# Z20K14xM register map
Vendor: Zhixin Semiconductor; Series: Z20K14xM; File version: 0.1.0
CPU: CM4 r0p1, little endian, no MPU, FPU, 4 interrupt priority bits
Registers are 32-bit, read-write, reset 0x0 unless marked. A register's access mark holds for its fields unless they carry their own. Offsets are from the block's base; [hi:lo] are bit positions; {n}, {i} and the like mark numbered series; 'fields as' and 'values as' point back to an identical list.

## CAN0
Base 0x40024000
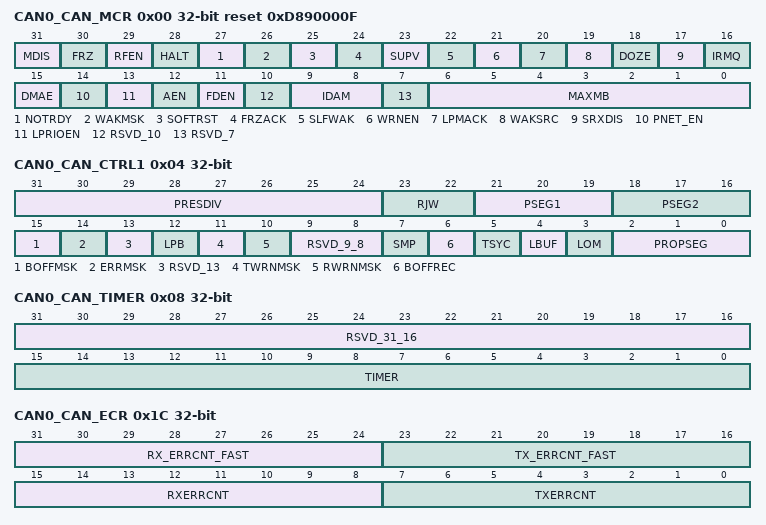
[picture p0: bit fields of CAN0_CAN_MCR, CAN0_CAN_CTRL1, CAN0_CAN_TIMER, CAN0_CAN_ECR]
0x00 CAN0_CAN_MCR reset 0xD890000F — CAN module configure register(CAN_MCR)
  [31] MDIS — Module Disable
  [30] FRZ — Freeze Enable
  [29] RFEN — Legacy Rx FIFO Enable
  [28] HALT — Halt CAN
  [27] NOTRDY — CAN Not Ready
  [26] WAKMSK — Wake Up Interrupt Mask
  [25] SOFTRST — Soft Reset
  [24] FRZACK — Freeze Mode Acknowledge
  [23] SUPV — Supervisor Mode
  [22] SLFWAK — Self Wake Up
  [21] WRNEN — Warning Interrupt Enable
  [20] LPMACK — Low-Power Mode Acknowledge
  [19] WAKSRC — Wake Up Source
  [18] DOZE — Doze Mode Enable
  [17] SRXDIS — Self Reception Disable
  [16] IRMQ — Individual Rx Masking And Queue Enable
  [15] DMAE — DMA Enable
  [14] PNET_EN — Pretended Networking Enable
  [13] LPRIOEN — Local Priority Enable
  [12] AEN — Abort Enable
  [11] FDEN — CAN FD operation enable
  [10] RSVD_10 — reserve
  [9:8] IDAM — ID Acceptance Mode
  [7] RSVD_7 — reserve
  [6:0] MAXMB — Reserved
0x04 CAN0_CAN_CTRL1 — CONTROL 1 register(CAN_CTRL1)
  [31:24] PRESDIV — Prescaler Division Factor
  [23:22] RJW — Resync Jump Width
  [21:19] PSEG1 — Phase segment 1
  [18:16] PSEG2 — Phase segment 2
  [15] BOFFMSK — Bus off interrupt mask
  [14] ERRMSK — Error interrupt mask
  [13] RSVD_13 — reserve
  [12] LPB — Loop Back Mode
  [11] TWRNMSK — Tx Warning Interrupt Mask
  [10] RWRNMSK — Rx Warning Interrupt Mask
  [9:8] RSVD_9_8 — reserve
  [7] SMP — CAN Bit Sampling
  [6] BOFFREC — Bus Off Recovery
  [5] TSYC — Timer Sync
  [4] LBUF — Lowest Buffer Transmitted First
  [3] LOM — Listen-Only Mode
  [2:0] PROPSEG — Propagation Segment
0x08 CAN0_CAN_TIMER — Free Running Timer register(CAN_TIMER)
  [31:16] RSVD_31_16 — reserve
  [15:0] TIMER — free running counter value
0x10 CAN0_CAN_RXMGMSK reset not defined — Rx mailbox global mask register(CAN_RXMGMSK)
  [31:0] MG — Rx mailbox global mask
0x14 CAN0_CAN_RX14MASK reset not defined — Rx 14 mask register(CAN_RX14MASK)
  [31:0] RX14M — Rx Buffer 14 Mask Bits
0x18 CAN0_CAN_RX15MASK reset not defined — Rx 15 mask register(CAN_RX15MASK)
  [31:0] RX15M — Rx Buffer 15 Mask Bits
0x1C CAN0_CAN_ECR — Error counter register(CAN_ECR)
  [31:24] RX_ERRCNT_FAST — Receive Error Counter for fast bits
  [23:16] TX_ERRCNT_FAST — Transmit Error Counter for fast bits
  [15:8] RXERRCNT — Receive Error Counter
  [7:0] TXERRCNT — Transmit Error Counter
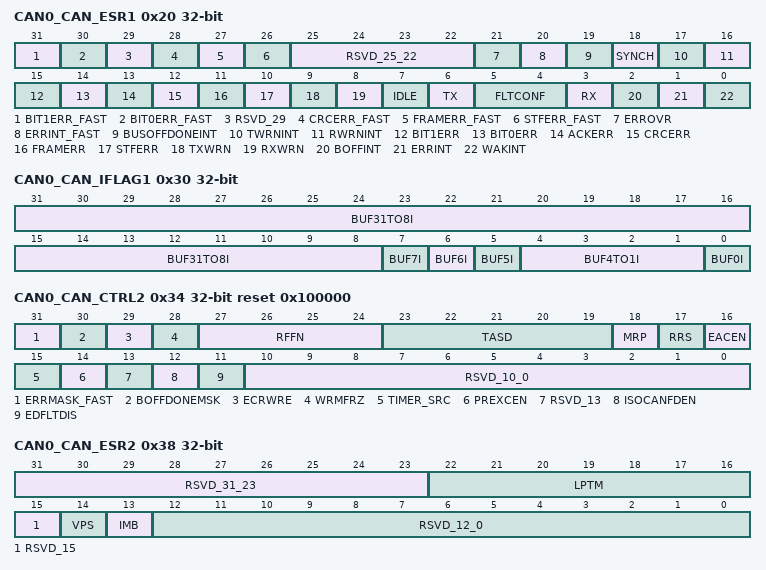
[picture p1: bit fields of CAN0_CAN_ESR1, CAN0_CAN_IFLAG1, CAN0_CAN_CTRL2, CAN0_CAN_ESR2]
0x20 CAN0_CAN_ESR1 — CAN error status register(CAN_ESR1)
  [31] BIT1ERR_FAST — Bit1 error in CAN_FD data phase
  [30] BIT0ERR_FAST — Bit0 error in CAN_FD data phase
  [29] RSVD_29 — reserve
  [28] CRCERR_FAST — CRC error in CAN_FD CRC phase
  [27] FRAMERR_FAST — Frame error of CAN_FD data phase
  [26] STFERR_FAST — Stuff erro of CAN_FD data phase.
  [25:22] RSVD_25_22 — reserve
  [21] ERROVR — error of overrun
  [20] ERRINT_FAST — error interrupt of errors detect in CAN_FD data phase
  [19] BUSOFFDONEINT — Bus off done interrupt
  [18] SYNCH — Synchronous
  [17] TWRNINT — Tx Warning Interrupt
  [16] RWRNINT — Rx warning Interrupt
  [15] BIT1ERR — Bit error of CAN non-fd
  [14] BIT0ERR — Bit0 error of CAN non-fd
  [13] ACKERR — Acknowledge error of non-fd
  [12] CRCERR — CRC error of non-fd
  [11] FRAMERR — frame error of non-fd
  [10] STFERR — stuff erro of non-fd
  [9] TXWRN — tx warning
  [8] RXWRN — Rx warning
  [7] IDLE
  [6] TX — Flexcan in transmission
  [5:4] FLTCONF — Fault confinement state
  [3] RX — Flexcan in Reception
  [2] BOFFINT — bus off interrupt
  [1] ERRINT — error interrupt
  [0] WAKINT — wakeup interrupt
0x24 CAN0_CAN_IMASK2 — Interrupt mask 2 register(CAN_IMASK2)
  [31:0] BUF63TO32M — Buffer MB i Mask
0x28 CAN0_CAN_IMASK1 — Interrupt mask 1 register(CAN_IMASK1)
  [31:0] BUF31TO0M — Buffer MB31 -0 Mask
0x2C CAN0_CAN_IFLAG2 — Interrupt flag 2 register(CAN_IFLAG2)
  [31:0] BUF63TO32I — Buffer MB63-32 Mask
0x30 CAN0_CAN_IFLAG1 — Interrupt flag 1 register(CAN_IFLAG1)
  [31:8] BUF31TO8I — Buffer8-31 interrupt
  [7] BUF7I — Buffer7 interrupt
  [6] BUF6I — Buffer6 interrupt
  [5] BUF5I — Buffer5 interrupt
  [4:1] BUF4TO1I — Buffer 1-4 interrupt
  [0] BUF0I — Buffer0 interrupt
0x34 CAN0_CAN_CTRL2 reset 0x100000 — Control 2 register(CAN_CTRL2)
  [31] ERRMASK_FAST — error mask of can-fd
  [30] BOFFDONEMSK — bus off done mask
  [29] ECRWRE — error correction register write enable
  [28] WRMFRZ — Write-Access To Memory In Freeze Mode
  [27:24] RFFN — Number of Rx FIFO Filters
  [23:19] TASD — Tx Arbitration Start Delay
  [18] MRP — Mailboxes Reception Priority
  [17] RRS — Remote Request Storing
  [16] EACEN — Entire Frame Arbitration Field Comparison Enable For Rx Mailboxes
  [15] TIMER_SRC — Timer Source
  [14] PREXCEN — Protocol Exception Enable
  [13] RSVD_13 — reserve
  [12] ISOCANFDEN — ISO CAN FD Enable
  [11] EDFLTDIS — Edge Filter Disable
  [10:0] RSVD_10_0 — reserve
0x38 CAN0_CAN_ESR2 — Error and Status 2 register(CAN_ESR2)
  [31:23] RSVD_31_23 — reserve
  [22:16] LPTM — Lowest Priority Tx Mailbox
  [15] RSVD_15 — reserve
  [14] VPS — Valid Priority Status
  [13] IMB — Inactive Mailbox
  [12:0] RSVD_12_0 — reserve
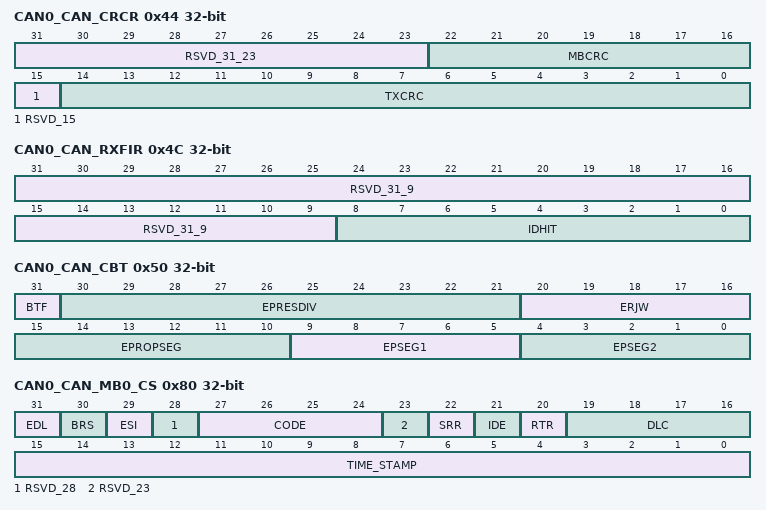
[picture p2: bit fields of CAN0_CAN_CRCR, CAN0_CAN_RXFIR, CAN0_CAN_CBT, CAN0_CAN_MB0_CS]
0x44 CAN0_CAN_CRCR — CRC register(CAN_CRCR)
  [31:23] RSVD_31_23 — reserve
  [22:16] MBCRC — CRC Mailbox
  [15] RSVD_15 — reserve
  [14:0] TXCRC — Transmitted CRC Value
0x48 CAN0_CAN_RXFGMASK reset not defined — Leagacy FIFO global mask register(CAN_RXFGMASK)
  [31:0] FGM — Rx FIFO Global Mask Bits
0x4C CAN0_CAN_RXFIR reset not defined — RX FIFO ID indicator(CAN_RXFIR)
  [31:9] RSVD_31_9 — reserve
  [8:0] IDHIT — ID Hit incicator
0x50 CAN0_CAN_CBT — CAN bit timing register(CAN_CBT)
  [31] BTF — Bit Timing Format Enable
  [30:21] EPRESDIV — Extended Prescaler Division Factor
  [20:16] ERJW — Extended Resync Jump Width
  [15:10] EPROPSEG — Extended Propagation Segment
  [9:5] EPSEG1 — Extended Phase Segment 1
  [4:0] EPSEG2 — Extended Phase Segment 2
0x68 CAN0_CAN_IMASK4 — Interrupt mask 4 register(CAN_IMASK4)
  [31:0] BUF127TO96M — Buffer MB 127-96 Mask
0x6C CAN0_CAN_IMASK3 — Interrupt mask 3 register(CAN_IMASK3)
  [31:0] BUF95TO64M — Buffer MB 95-64 Mask
0x70 CAN0_CAN_IFLAG4 — Interrupt flag 4 register(CAN_IFLAG4)
  [31:0] BUF127TO96I — Buffer MB 127-96 Interrupt
0x74 CAN0_CAN_IFLAG3 — Interrupt flag 3 register(CAN_IFLAG3)
  [31:0] BUF95TO64I — Buffer MB 95-64 Interrupt
0x80 CAN0_CAN_MB0_CS reset not defined — reserve
  [31] EDL — Extended Data Length
  [30] BRS — Bit Rate Switch
  [29] ESI — Error State Indicator
  [28] RSVD_28 — reserve
  [27:24] CODE — Message Buffer Code
  [23] RSVD_23 — reserve
  [22] SRR — Substitute Remote Request
  [21] IDE — ID Extended Bit
  [20] RTR — Remote Transmission Request
  [19:16] DLC — Length of Data in Bytes
  [15:0] TIME_STAMP — Free-Running Counter Time Stamp
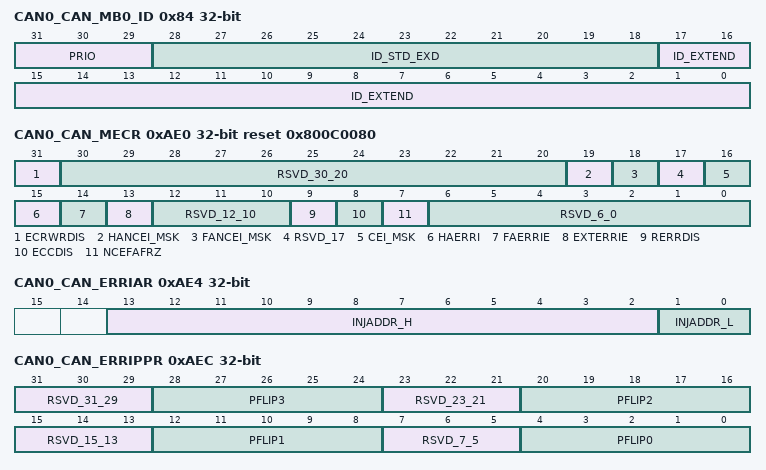
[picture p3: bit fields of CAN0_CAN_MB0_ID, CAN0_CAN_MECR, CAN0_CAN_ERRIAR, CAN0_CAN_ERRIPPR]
0x84 CAN0_CAN_MB0_ID reset not defined — Message buffer ID register(CAN_MB0_ID)
  [31:29] PRIO — Local priority
  [28:18] ID_STD_EXD — Frame Identifier
  [17:0] ID_EXTEND — Frame Identifier
0x88 CAN0_CAN_MB0_DATA03 reset not defined — Message buffer date03 register(CAN_MB0_DATA03)
  [31:0] DATA_BYTE03
0x8C CAN0_CAN_MB0_DATA47 reset not defined — Message buffer date47 register(CAN_MB0_DAT47)
  [31:0] DATA_BYTE47 — data byte0-3
0x880 CAN0_CAN_RXIMRn reset not defined — RX individual mask register(CAN_RXIMRn)
  [31:0] MI — Individual Mask Bits
0xAE0 CAN0_CAN_MECR reset 0x800C0080 — Memory error control register(CAN_MECR)
  [31] ECRWRDIS — Error Configuration Register Write Disable
  [30:20] RSVD_30_20 — reserve
  [19] HANCEI_MSK — Host Access with Non-Correctable Errors Interrupt Mask
  [18] FANCEI_MSK — CAN Access With Non-Correctable Errors Interrupt Mask
  [17] RSVD_17 — reserve
  [16] CEI_MSK — Correctable Errors Interrupt Mask
  [15] HAERRI — Host Access Error Injection Enable
  [14] FAERRIE — CAN Access Error Injection Enable
  [13] EXTERRIE — Extended Error Injection
  [12:10] RSVD_12_10 — reserve
  [9] RERRDIS — Error Report Disable
  [8] ECCDIS — Error Correction Disable
  [7] NCEFAFRZ — Non-Correctable Errors In CAN Access Put Device In Freeze Mode
  [6:0] RSVD_6_0 — reserve
0xAE4 CAN0_CAN_ERRIAR — Error injection address regsiter(CAN_ERRIAR)
  [13:2] INJADDR_H — Error Injection Address High
  [1:0] INJADDR_L — Error Injection Address Low
0xAE8 CAN0_CAN_ERRIDPR — Error injection data pattern register(CAN_ERRIDPR)
  [31:0] DFLIP — Data Flip Pattern
0xAEC CAN0_CAN_ERRIPPR — Error injection parity pattern register(CAN_ERRIPPR)
  [31:29] RSVD_31_29 — reserve
  [28:24] PFLIP3 — Parity Flip Pattern For Byte 3 (most significant)
  [23:21] RSVD_23_21 — reserve
  [20:16] PFLIP2 — Parity Flip Pattern For Byte 2
  [15:13] RSVD_15_13 — reserve
  [12:8] PFLIP1 — Parity Flip Pattern For Byte 1
  [7:5] RSVD_7_5 — reserve
  [4:0] PFLIP0 — Parity Flip Pattern For Byte 0
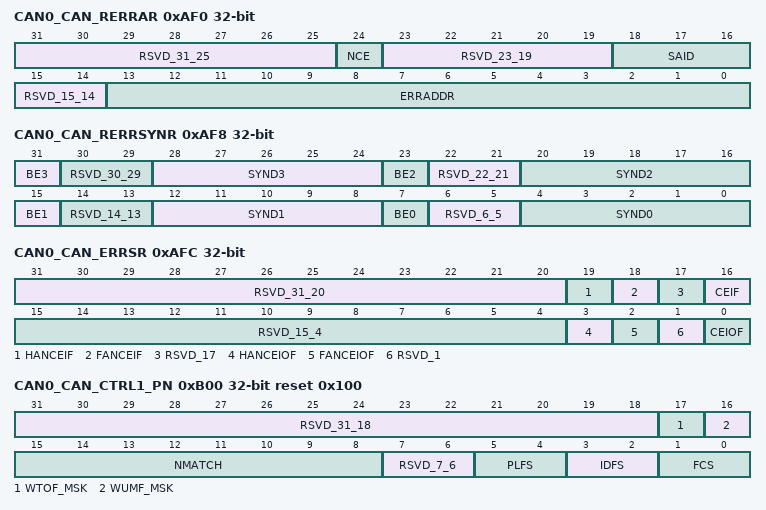
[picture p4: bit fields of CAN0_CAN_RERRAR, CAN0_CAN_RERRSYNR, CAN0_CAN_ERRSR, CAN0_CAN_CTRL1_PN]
0xAF0 CAN0_CAN_RERRAR — Error report address register(CAN_RERRAR)
  [31:25] RSVD_31_25 — reserve
  [24] NCE — Non-Correctable Error: Indicates that the report is due to a non-correctable error
  [23:19] RSVD_23_19 — reserve
  [18:16] SAID — SAID[2]: Identification of the requestor of the memory read request SAID[1]: Details of FlexCAN operation SAID[0]: Operation that requested the memory read
  [15:14] RSVD_15_14 — reserve
  [13:0] ERRADDR — Address Where the Error was Detected
0xAF4 CAN0_CAN_RERRDR — Error report data register(CAN_RERRDR)
  [31:0] RDATA — Raw data word read from memory with error
0xAF8 CAN0_CAN_RERRSYNR — Error report Syndrome reigster(CAN_RERRSYNR)
  [31] BE3 — Byte Enabled For Byte 3 (most significant)
  [30:29] RSVD_30_29 — reserve
  [28:24] SYND3 — Error Syndrome For Byte 3 (most significant)
  [23] BE2 — Error Syndrome For Byte 3 (most significant)
  [22:21] RSVD_22_21 — reserve
  [20:16] SYND2 — Error Syndrome For Byte 2
  [15] BE1 — Byte Enabled For Byte 1
  [14:13] RSVD_14_13 — reserve
  [12:8] SYND1 — Error Syndrome For Byte 1
  [7] BE0 — Byte Enabled For Byte 0 (least significant)
  [6:5] RSVD_6_5 — reserve
  [4:0] SYND0 — Error Syndrome For Byte 0
0xAFC CAN0_CAN_ERRSR — Error status register(CAN_ERRSR)
  [31:20] RSVD_31_20 — reserve
  [19] HANCEIF — Host Access with Non-Correctable Error Interrupt Flag
  [18] FANCEIF — CAN Access with Non-Correctable Error Interrupt Flag
  [17] RSVD_17 — reserve
  [16] CEIF — Correctable Error Interrupt Flag
  [15:4] RSVD_15_4 — reserve
  [3] HANCEIOF — Host Access with Non-Correctable Error Interrupt Overrun Flag
  [2] FANCEIOF — CAN Access With Non-Correctable Error Interrupt Overrun Flag
  [1] RSVD_1 — reserve
  [0] CEIOF — Correctable Error Interrupt Overrun Flag
0xB00 CAN0_CAN_CTRL1_PN reset 0x100 — Pretend network control 1 register(CAN_CTRL1_PN)
  [31:18] RSVD_31_18 — reserve
  [17] WTOF_MSK — Wake Up by Timeout Flag Mask Bit
  [16] WUMF_MSK — Wake Up by Match Flag Mask Bit
  [15:8] NMATCH — Number of Messages Matching the Same Filtering Criteria
  [7:6] RSVD_7_6 — reserve
  [5:4] PLFS — Payload Filtering Selection
  [3:2] IDFS — ID Filtering Selection
  [1:0] FCS — Filtering Combination Selection
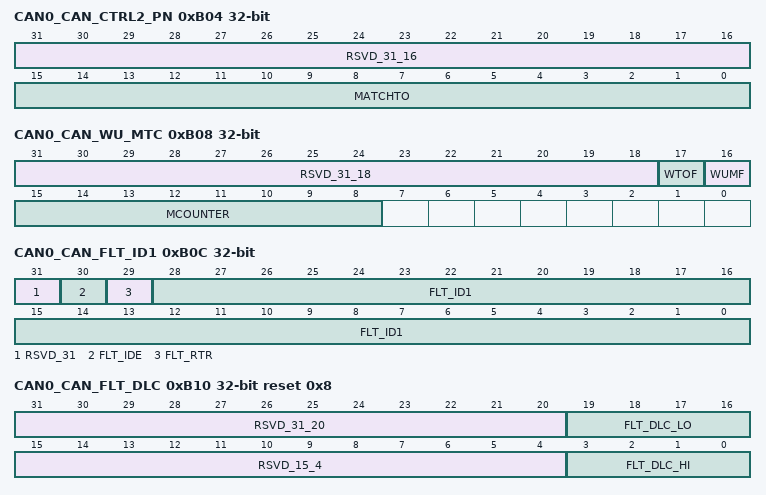
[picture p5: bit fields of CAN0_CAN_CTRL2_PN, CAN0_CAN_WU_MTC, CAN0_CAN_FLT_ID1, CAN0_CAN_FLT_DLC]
0xB04 CAN0_CAN_CTRL2_PN — Pretend network control 2 register(CAN_CTRL2_PN)
  [31:16] RSVD_31_16 — reserve
  [15:0] MATCHTO — Timeout for No Message Matching the Filtering Criteria
0xB08 CAN0_CAN_WU_MTC — Pretend network wakeup match register(CAN_WU_MTC)
  [31:18] RSVD_31_18 — reserve
  [17] WTOF — Wake Up by Timeout Flag Bit
  [16] WUMF — Wake Up by Match Flag Bit
  [15:8] MCOUNTER — Number of Matches when in Pretended Networking
0xB0C CAN0_CAN_FLT_ID1 — Pretend network ID filter 1 register(CAN_FLT_ID1)
  [31] RSVD_31 — reserve
  [30] FLT_IDE — Number of Matches when in Pretended Networking
  [29] FLT_RTR — Remote Transmission Request Filter
  [28:0] FLT_ID1 — ID Filter 1 for Pretended Networking Filtering
0xB10 CAN0_CAN_FLT_DLC reset 0x8 — Pretend network DLC filter register(CAN_FLT_DLC)
  [31:20] RSVD_31_20 — reserve
  [19:16] FLT_DLC_LO — Lower Limit for Length of Data Bytes Filter
  [15:4] RSVD_15_4 — reserve
  [3:0] FLT_DLC_HI — Upper Limit for Length of Data Bytes Filter
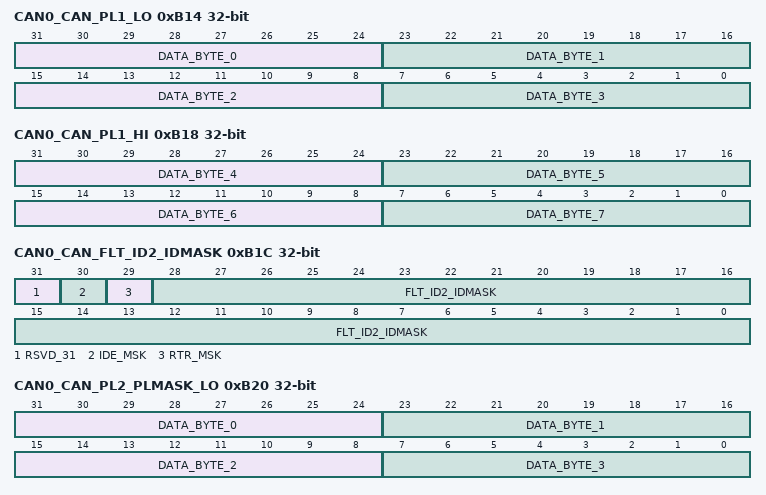
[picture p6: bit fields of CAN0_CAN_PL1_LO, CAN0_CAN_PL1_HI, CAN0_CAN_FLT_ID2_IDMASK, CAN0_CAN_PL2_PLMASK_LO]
0xB14 CAN0_CAN_PL1_LO — Pretend network payload low filter 1 register(CAN_PL1_LO)
  [31-8n:24-8n] DATA_BYTE_{n} (n=0..3) — Reserved
0xB18 CAN0_CAN_PL1_HI — Pretend network payload high filter 1 register(CAN_PL1_HI)
  [63-8n:56-8n] DATA_BYTE_{n} (n=4..7) — Reserved
0xB1C CAN0_CAN_FLT_ID2_IDMASK — Pretended Networking ID Filter 2 Register / ID Mask Register(CAN_FLT_ID2_IDMASK)
  [31] RSVD_31 — reserve
  [30] IDE_MSK — ID Extended Mask Bit
  [29] RTR_MSK — Remote Transmission Request Mask Bit
  [28:0] FLT_ID2_IDMASK — ID Filter 2 for Pretended Networking Filtering/ ID Mask Bits for Pretended Networking ID Filtering
0xB20 CAN0_CAN_PL2_PLMASK_LO — Pretended Networking Payload Low Filter 2 Register / Payload Low Mask Register(CAN_PL2_PLMASK_LO)
  [31-8n:24-8n] DATA_BYTE_{n} (n=0..3) — Reserved
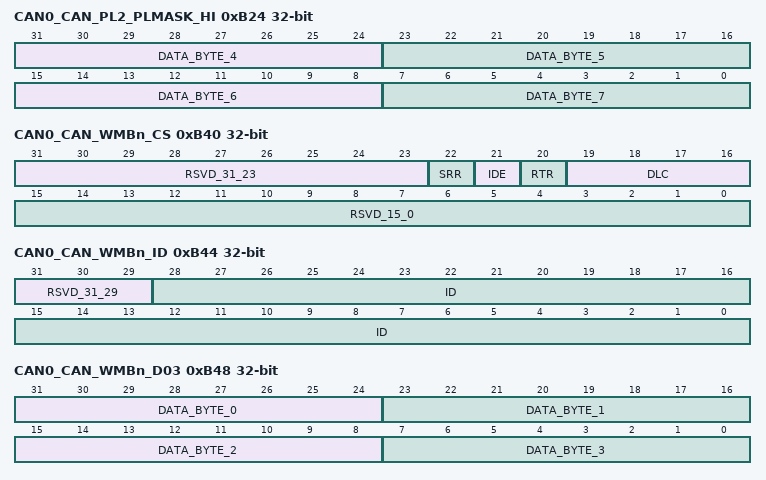
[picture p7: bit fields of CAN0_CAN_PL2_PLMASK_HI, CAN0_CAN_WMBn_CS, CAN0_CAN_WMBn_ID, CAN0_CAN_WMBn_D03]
0xB24 CAN0_CAN_PL2_PLMASK_HI — Pretended Networking Payload High Filter 2 low order bits / Payload High Mask Register (PL2_PLMASK_HI)
  [63-8n:56-8n] DATA_BYTE_{n} (n=4..7) — Reserved
0xB40 CAN0_CAN_WMBn_CS — Wake Up Message Buffer Register for C/S(CAN_WMBn_CS)
  [31:23] RSVD_31_23 — reserve
  [22] SRR — Substitute Remote Request
  [21] IDE — ID Extended Bit
  [20] RTR — Remote Transmission Request Bit
  [19:16] DLC — Length of Data in Bytes
  [15:0] RSVD_15_0 — reserve
0xB44 CAN0_CAN_WMBn_ID — Wake Up Message Buffer Register for ID(CAN_WMBn_ID)
  [31:29] RSVD_31_29 — reserve
  [28:0] ID — Received ID under Pretended Networking mode
0xB48 CAN0_CAN_WMBn_D03 — Wake Up Message Buffer Register for Data 0-3(CAN_WMBn_D03)
  [31-8n:24-8n] DATA_BYTE_{n} (n=0..3) — Reserved
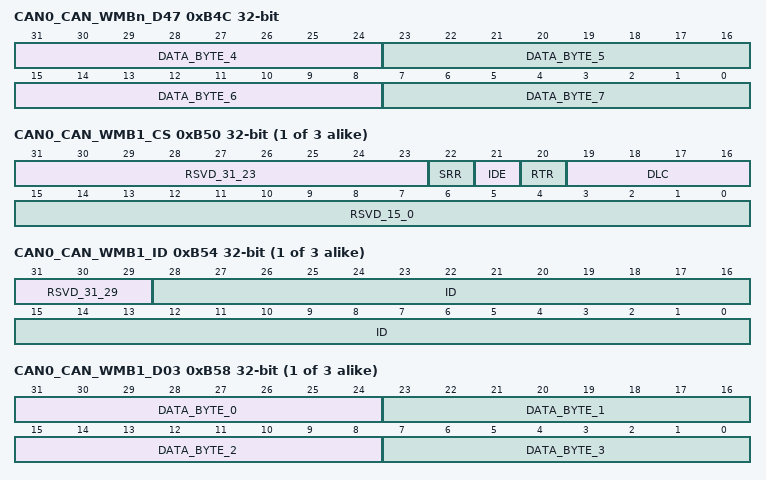
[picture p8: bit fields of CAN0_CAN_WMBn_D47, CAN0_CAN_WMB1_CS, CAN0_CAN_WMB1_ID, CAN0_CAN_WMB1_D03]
0xB4C CAN0_CAN_WMBn_D47 — Wake Up Message Buffer Register for Data 4-7(CAN_WMBn_D47)
  [63-8n:56-8n] DATA_BYTE_{n} (n=4..7) — Reserved
{0xB40+0x10*i} CAN0_CAN_WMB{i}_CS (i=1..3) — Wake Up Message Buffer Register for C/S(CAN_WMBn_CS)
  fields as CAN0_CAN_WMBn_CS
{0xB44+0x10*i} CAN0_CAN_WMB{i}_ID (i=1..3) — Wake Up Message Buffer Register for ID(CAN_WMBn_ID)
  fields as CAN0_CAN_WMBn_ID
{0xB48+0x10*i} CAN0_CAN_WMB{i}_D03 (i=1..3) — Wake Up Message Buffer Register for Data 0-3(CAN_WMBn_D03)
  [31-8n:24-8n] DATA_BYTE_{n} (n=0..3) — Reserved
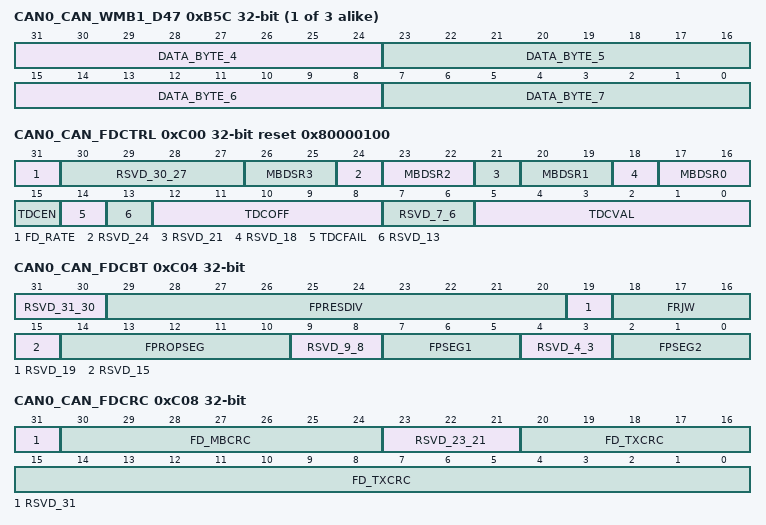
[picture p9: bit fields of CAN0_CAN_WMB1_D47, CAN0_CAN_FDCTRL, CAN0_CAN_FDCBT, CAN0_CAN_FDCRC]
{0xB4C+0x10*i} CAN0_CAN_WMB{i}_D47 (i=1..3) — Wake Up Message Buffer Register for Data 4-7(CAN_WMBn_D47)
  [63-8n:56-8n] DATA_BYTE_{n} (n=4..7) — Reserved
0xC00 CAN0_CAN_FDCTRL reset 0x80000100 — CAN FD control register(CAN_FDCTRL)
  [31] FD_RATE — Bit Rate Switch Enable
  [30:27] RSVD_30_27 — reserve
  [3n+17:3n+16] MBDSR{n} (n=0..3) — Message Buffer Data Size for Region {n}
  [24] RSVD_24 — reserve
  [21] RSVD_21 — reserve
  [18] RSVD_18 — reserve
  [15] TDCEN — Transceiver Delay Compensation Enable
  [14] TDCFAIL — Transceiver Delay Compensation Fail
  [13] RSVD_13 — reserve
  [12:8] TDCOFF — Transceiver Delay Compensation Offset
  [7:6] RSVD_7_6 — reserve
  [5:0] TDCVAL — Transceiver Delay Compensation Value
0xC04 CAN0_CAN_FDCBT — CAN FD bit timing control register(CAN_FDCBT)
  [31:30] RSVD_31_30 — reserve
  [29:20] FPRESDIV — Fast Prescaler Division Factor
  [19] RSVD_19 — reserve
  [18:16] FRJW — Fast Resync Jump Width
  [15] RSVD_15 — reserve
  [14:10] FPROPSEG — Fast Propagation Segment
  [9:8] RSVD_9_8 — reserve
  [7:5] FPSEG1 — Fast Phase Segment 1
  [4:3] RSVD_4_3 — reserve
  [2:0] FPSEG2 — Fast Phase Segment 2
0xC08 CAN0_CAN_FDCRC — CAN FD CRC register(CAN_FDCRC)
  [31] RSVD_31 — reserve
  [30:24] FD_MBCRC — CRC Mailbox Number for FD_TXCRC
  [23:21] RSVD_23_21 — reserve
  [20:0] FD_TXCRC — Extended Transmitted CRC value

## CAN1
Base 0x40025000
Registers as CAN0 (with CAN0 read as CAN1).

## CAN2
Base 0x40038000
Registers as CAN0 (with CAN0 read as CAN2).

## CAN3
Base 0x40039000
Registers as CAN0 (with CAN0 read as CAN3).

## CAN4
Base 0x40044000
Registers as CAN0 (with CAN0 read as CAN4).

## CAN5
Base 0x40045000
Registers as CAN0 (with CAN0 read as CAN5).

## CAN6
Base 0x40056000
Registers as CAN0 (with CAN0 read as CAN6).

## CAN7
Base 0x40057000
Registers as CAN0 (with CAN0 read as CAN7).
